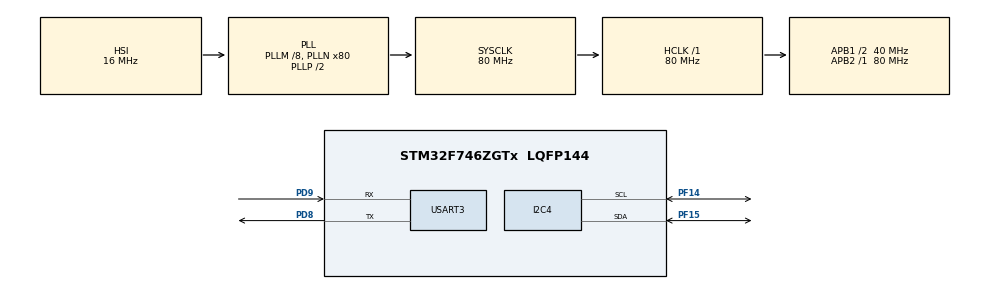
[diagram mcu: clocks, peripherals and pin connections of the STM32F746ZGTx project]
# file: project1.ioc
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I2C4.Timing=0x00909BEB
Mcu.Family=STM32F7
Mcu.Name=STM32F746ZGTx
Mcu.Package=LQFP144
NVIC.PriorityGroup=NVIC_PRIORITYGROUP_4
PD8.Mode=Asynchronous
PD8.Signal=USART3_TX
PD9.Mode=Asynchronous
PD9.Signal=USART3_RX
PF14.Mode=I2C
PF14.Signal=I2C4_SCL
PF15.Mode=I2C
PF15.Signal=I2C4_SDA
ProjectManager.HeapSize=0x200
ProjectManager.StackSize=0x400
ProjectManager.TargetToolchain=STM32CubeIDE
RCC.AHBFreq_Value=80000000
RCC.APB1CLKDivider=RCC_HCLK_DIV2
RCC.APB1Freq_Value=40000000
RCC.APB1TimFreq_Value=80000000
RCC.APB2Freq_Value=80000000
RCC.APB2TimFreq_Value=80000000
RCC.CortexFreq_Value=80000000
RCC.HCLKFreq_Value=80000000
RCC.HSE_VALUE=25000000
RCC.HSI_VALUE=16000000
RCC.LSE_VALUE=32768
RCC.PLLM=8
RCC.PLLN=80
RCC.SYSCLKFreq_VALUE=80000000
RCC.SYSCLKSource=RCC_SYSCLKSOURCE_PLLCLK
RCC.USBFreq_Value=80000000
RCC.VCOOutputFreq_Value=160000000
USART3.VirtualMode-Asynchronous=VM_ASYNC
board=custom

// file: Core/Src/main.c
/* USER CODE BEGIN Header */
/**
  ******************************************************************************
  * @file           : main.c
  * @brief          : Main program body
  ******************************************************************************
  * @attention
  *
  * <h2><center>&copy; Copyright (c) 2021 STMicroelectronics.
  * All rights reserved.</center></h2>
  *
  * This software component is licensed by ST under BSD 3-Clause license,
  * the "License"; You may not use this file except in compliance with the
  * License. You may obtain a copy of the License at:
  *                        opensource.org/licenses/BSD-3-Clause
  *
  ******************************************************************************
  */
/* USER CODE END Header */
#include <stdio.h>
#include "main.h"
#include "4263_MPU6050.h"

/* USER CODE BEGIN PTD */

#define TIME_DELAY 50    // millisecconds

/* USER CODE END PTD */

I2C_HandleTypeDef hi2c4;

UART_HandleTypeDef huart3;

void SystemClock_Config(void);
static void MX_GPIO_Init(void);
static void MX_I2C4_Init(void);
static void MX_USART3_UART_Init(void);

int main(void)
{
  /* USER CODE BEGIN 1 */

  float AccelData[3];
  float GyroData[3];

  /* USER CODE END 1 */

  /* MCU Configuration--------------------------------------------------------*/

  /* Reset of all peripherals, Initializes the Flash interface and the Systick. */
  HAL_Init();

  /* Configure the system clock */
  SystemClock_Config();

  /* Initialize all configured peripherals */
  MX_GPIO_Init();
  MX_I2C4_Init();
  MX_USART3_UART_Init();
  /* USER CODE BEGIN 2 */

  MPU6050_init(&hi2c4);

  /* USER CODE END 2 */

  /* Infinite loop */
  /* USER CODE BEGIN WHILE */
  while (1)
  {

    MPU6050_Read_Accel(&hi2c4, AccelData);
    MPU6050_Read_Gyro(&hi2c4, GyroData);
    MPU6050_SerialOscilloscope(&huart3, AccelData, GyroData);

    HAL_Delay(TIME_DELAY);
    /* USER CODE END WHILE */

  }
}

void SystemClock_Config(void)
{
  RCC_OscInitTypeDef RCC_OscInitStruct = {0};
  RCC_ClkInitTypeDef RCC_ClkInitStruct = {0};
  RCC_PeriphCLKInitTypeDef PeriphClkInitStruct = {0};

  /** Configure the main internal regulator output voltage
  */
  __HAL_RCC_PWR_CLK_ENABLE();
  __HAL_PWR_VOLTAGESCALING_CONFIG(PWR_REGULATOR_VOLTAGE_SCALE3);
  /** Initializes the RCC Oscillators according to the specified parameters
  * in the RCC_OscInitTypeDef structure.
  */
  RCC_OscInitStruct.OscillatorType = RCC_OSCILLATORTYPE_HSI;
  RCC_OscInitStruct.HSIState = RCC_HSI_ON;
  RCC_OscInitStruct.HSICalibrationValue = RCC_HSICALIBRATION_DEFAULT;
  RCC_OscInitStruct.PLL.PLLState = RCC_PLL_ON;
  RCC_OscInitStruct.PLL.PLLSource = RCC_PLLSOURCE_HSI;
  RCC_OscInitStruct.PLL.PLLM = 8;
  RCC_OscInitStruct.PLL.PLLN = 80;
  RCC_OscInitStruct.PLL.PLLP = RCC_PLLP_DIV2;
  RCC_OscInitStruct.PLL.PLLQ = 2;
  if (HAL_RCC_OscConfig(&RCC_OscInitStruct) != HAL_OK)
  {
    Error_Handler();
  }
  /** Initializes the CPU, AHB and APB buses clocks
  */
  RCC_ClkInitStruct.ClockType = RCC_CLOCKTYPE_HCLK|RCC_CLOCKTYPE_SYSCLK
                              |RCC_CLOCKTYPE_PCLK1|RCC_CLOCKTYPE_PCLK2;
  RCC_ClkInitStruct.SYSCLKSource = RCC_SYSCLKSOURCE_PLLCLK;
  RCC_ClkInitStruct.AHBCLKDivider = RCC_SYSCLK_DIV1;
  RCC_ClkInitStruct.APB1CLKDivider = RCC_HCLK_DIV2;
  RCC_ClkInitStruct.APB2CLKDivider = RCC_HCLK_DIV1;

  if (HAL_RCC_ClockConfig(&RCC_ClkInitStruct, FLASH_LATENCY_2) != HAL_OK)
  {
    Error_Handler();
  }
  PeriphClkInitStruct.PeriphClockSelection = RCC_PERIPHCLK_USART3|RCC_PERIPHCLK_I2C4;
  PeriphClkInitStruct.Usart3ClockSelection = RCC_USART3CLKSOURCE_PCLK1;
  PeriphClkInitStruct.I2c4ClockSelection = RCC_I2C4CLKSOURCE_PCLK1;
  if (HAL_RCCEx_PeriphCLKConfig(&PeriphClkInitStruct) != HAL_OK)
  {
    Error_Handler();
  }
}

static void MX_I2C4_Init(void)
{

  hi2c4.Instance = I2C4;
  hi2c4.Init.Timing = 0x00909BEB;
  hi2c4.Init.OwnAddress1 = 0;
  hi2c4.Init.AddressingMode = I2C_ADDRESSINGMODE_7BIT;
  hi2c4.Init.DualAddressMode = I2C_DUALADDRESS_DISABLE;
  hi2c4.Init.OwnAddress2 = 0;
  hi2c4.Init.OwnAddress2Masks = I2C_OA2_NOMASK;
  hi2c4.Init.GeneralCallMode = I2C_GENERALCALL_DISABLE;
  hi2c4.Init.NoStretchMode = I2C_NOSTRETCH_DISABLE;
  if (HAL_I2C_Init(&hi2c4) != HAL_OK)
  {
    Error_Handler();
  }
  /** Configure Analogue filter
  */
  if (HAL_I2CEx_ConfigAnalogFilter(&hi2c4, I2C_ANALOGFILTER_ENABLE) != HAL_OK)
  {
    Error_Handler();
  }
  /** Configure Digital filter
  */
  if (HAL_I2CEx_ConfigDigitalFilter(&hi2c4, 0) != HAL_OK)
  {
    Error_Handler();
  }

}

static void MX_USART3_UART_Init(void)
{

  huart3.Instance = USART3;
  huart3.Init.BaudRate = 115200;
  huart3.Init.WordLength = UART_WORDLENGTH_8B;
  huart3.Init.StopBits = UART_STOPBITS_1;
  huart3.Init.Parity = UART_PARITY_NONE;
  huart3.Init.Mode = UART_MODE_TX_RX;
  huart3.Init.HwFlowCtl = UART_HWCONTROL_NONE;
  huart3.Init.OverSampling = UART_OVERSAMPLING_16;
  huart3.Init.OneBitSampling = UART_ONE_BIT_SAMPLE_DISABLE;
  huart3.AdvancedInit.AdvFeatureInit = UART_ADVFEATURE_NO_INIT;
  if (HAL_UART_Init(&huart3) != HAL_OK)
  {
    Error_Handler();
  }

}

static void MX_GPIO_Init(void)
{

  /* GPIO Ports Clock Enable */
  __HAL_RCC_GPIOF_CLK_ENABLE();
  __HAL_RCC_GPIOD_CLK_ENABLE();

}

void Error_Handler(void)
{
  __disable_irq();
  while (1)
  {
  }
}

/************************ (C) COPYRIGHT STMicroelectronics *****END OF FILE****/
